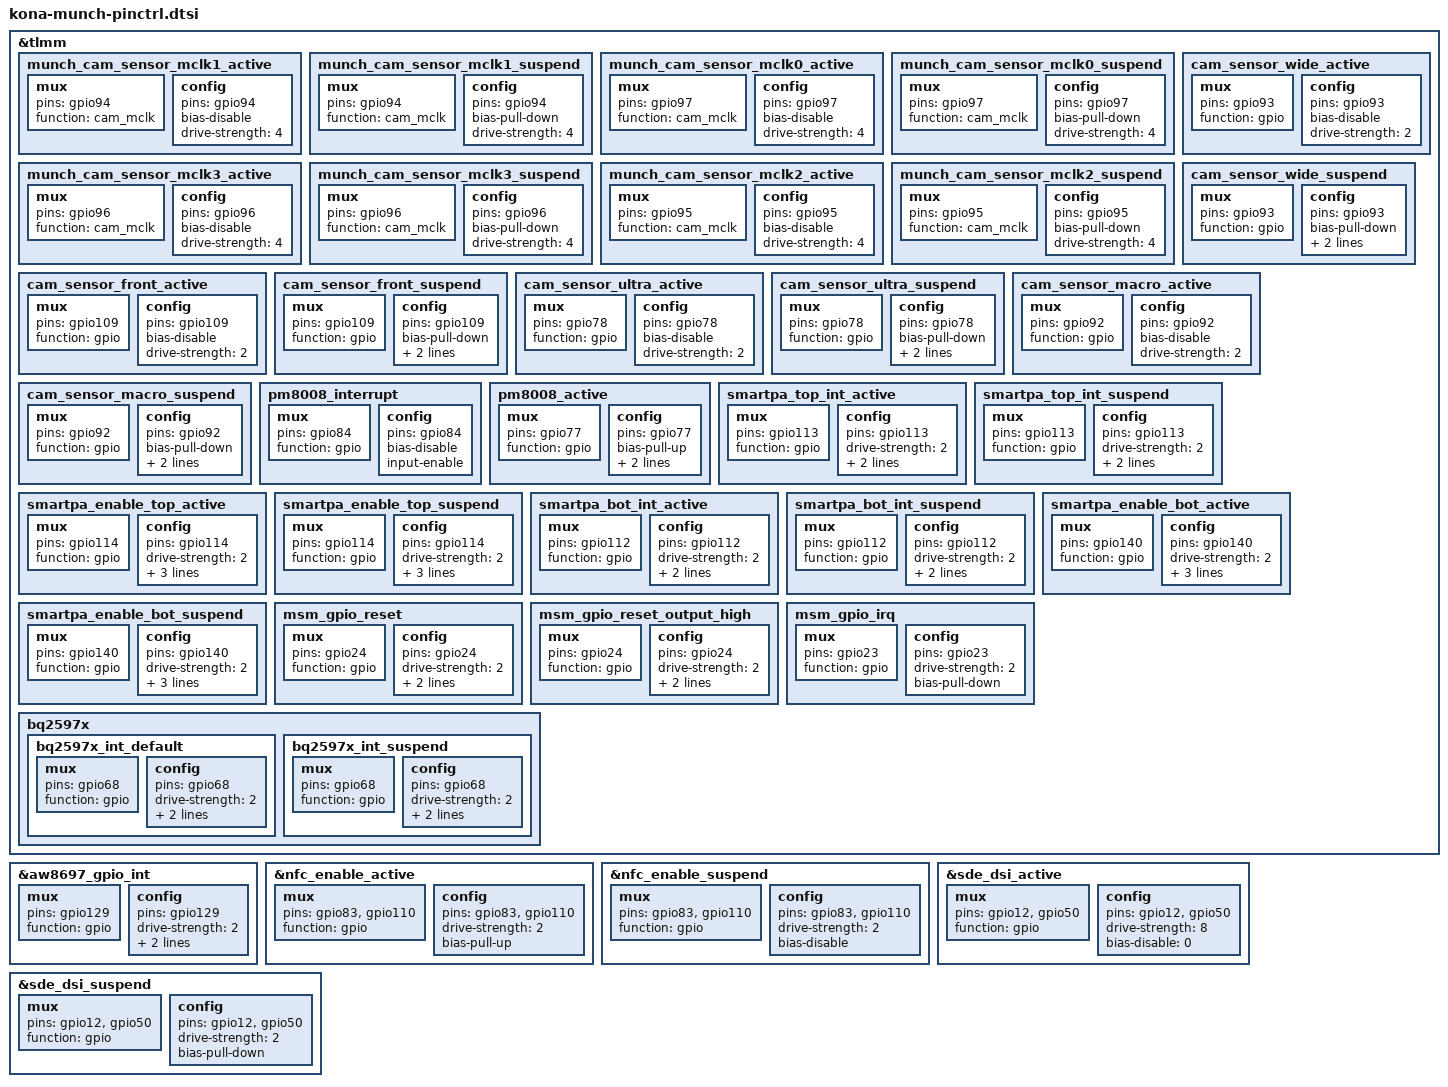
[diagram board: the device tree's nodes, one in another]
// SPDX-License-Identifier: GPL-2.0
/* Copyright (c) 2022, The Linux Foundation. All rights reserved.
 *
 * This program is free software; you can redistribute it and/or modify
 * it under the terms of the GNU General Public License version 2 and
 * only version 2 as published by the Free Software Foundation.
 *
 * This program is distributed in the hope that it will be useful,
 * but WITHOUT ANY WARRANTY; without even the implied warranty of
 * MERCHANTABILITY or FITNESS FOR A PARTICULAR PURPOSE.  See the
 * GNU General Public License for more details.
 */

&tlmm {
	munch_cam_sensor_mclk1_active: munch_cam_sensor_mclk1_active {
		mux {
			pins = "gpio94";
			function = "cam_mclk";
		};

		config {
			pins = "gpio94";
			bias-disable; /* No PULL */
			drive-strength = <4>; /* 4 MA */
		};
	};

	munch_cam_sensor_mclk1_suspend: munch_cam_sensor_mclk1_suspend {
		mux {
			pins = "gpio94";
			function = "cam_mclk";
		};

		config {
			pins = "gpio94";
			bias-pull-down; /* PULL DOWN */
			drive-strength = <4>; /* 4 MA */
		};
	};

	munch_cam_sensor_mclk0_active: munch_cam_sensor_mclk0_active {
		mux {
			pins = "gpio97";
			function = "cam_mclk";
		};

		config {
			pins = "gpio97";
			bias-disable; /* No PULL */
			drive-strength = <4>; /* 4 MA */
		};
	};

	munch_cam_sensor_mclk0_suspend: munch_cam_sensor_mclk0_suspend {
		mux {
			pins = "gpio97";
			function = "cam_mclk";
		};

		config {
			pins = "gpio97";
			bias-pull-down; /* PULL DOWN */
			drive-strength = <4>; /* 4 MA */
		};
	};

	munch_cam_sensor_mclk3_active: munch_cam_sensor_mclk3_active {
		mux {
			pins = "gpio96";
			function = "cam_mclk";
		};

		config {
			pins = "gpio96";
			bias-disable; /* No PULL */
			drive-strength = <4>; /* 4 MA */
		};
	};

	munch_cam_sensor_mclk3_suspend: munch_cam_sensor_mclk3_suspend {
		mux {
			pins = "gpio96";
			function = "cam_mclk";
		};

		config {
			pins = "gpio96";
			bias-pull-down; /* PULL DOWN */
			drive-strength = <4>; /* 4 MA */
		};
	};

	munch_cam_sensor_mclk2_active: munch_cam_sensor_mclk2_active {
		mux {
			pins = "gpio95";
			function = "cam_mclk";
		};

		config {
			pins = "gpio95";
			bias-disable; /* No PULL */
			drive-strength = <4>; /* 4 MA */
		};
	};

	munch_cam_sensor_mclk2_suspend: munch_cam_sensor_mclk2_suspend {
		mux {
			pins = "gpio95";
			function = "cam_mclk";
		};

		config {
			pins = "gpio95";
			bias-pull-down; /* PULL DOWN */
			drive-strength = <4>; /* 4 MA */
		};
	};

	cam_sensor_wide_active: cam_sensor_wide_active {
		mux {
			pins = "gpio93";
			function = "gpio";
		};

		config {
			pins = "gpio93";
			bias-disable; /* No PULL */
			drive-strength = <2>; /* 2 MA */
		};
	};

	cam_sensor_wide_suspend: cam_sensor_wide_suspend {
		mux {
			pins = "gpio93";
			function = "gpio";
		};

		config {
			pins = "gpio93";
			bias-pull-down; /* PULL DOWN */
			drive-strength = <2>; /* 2 MA */
			output-low;
		};
	};

	cam_sensor_front_active: cam_sensor_front_active {
		mux {
			pins = "gpio109";
			function = "gpio";
		};

		config {
			pins = "gpio109";
			bias-disable; /* No PULL */
			drive-strength = <2>; /* 2 MA */
		};
	};

	cam_sensor_front_suspend: cam_sensor_front_suspend {
		mux {
			pins = "gpio109";
			function = "gpio";
		};

		config {
			pins = "gpio109";
			bias-pull-down; /* PULL DOWN */
			drive-strength = <2>; /* 2 MA */
			output-low;
		};
	};

	cam_sensor_ultra_active: cam_sensor_ultra_active {
		mux {
			pins = "gpio78";
			function = "gpio";
		};

		config {
			pins = "gpio78";
			bias-disable; /* No PULL */
			drive-strength = <2>; /* 2 MA */
		};
	};

	cam_sensor_ultra_suspend: cam_sensor_ultra_suspend {
		mux {
			pins = "gpio78";
			function = "gpio";
		};

		config {
			pins = "gpio78";
			bias-pull-down; /* PULL DOWN */
			drive-strength = <2>; /* 2 MA */
			output-low;
		};
	};

	cam_sensor_macro_active: cam_sensor_macro_active {
		mux {
			pins = "gpio92";
			function = "gpio";
		};

		config {
			pins = "gpio92";
			bias-disable; /* No PULL */
			drive-strength = <2>; /* 2 MA */
		};
	};

	cam_sensor_macro_suspend: cam_sensor_macro_suspend {
		mux {
			pins = "gpio92";
			function = "gpio";
		};

		config {
			pins = "gpio92";
			bias-pull-down; /* PULL DOWN */
			drive-strength = <2>; /* 2 MA */
			output-low;
		};
	};

	pm8008_interrupt: pm8008_interrupt {
		mux {
			pins = "gpio84";
			function = "gpio";
		};

		config {
			pins = "gpio84";
			bias-disable;
			input-enable;
		};
	};

	pm8008_active: pm8008_active {
		mux {
			pins = "gpio77";
			function = "gpio";
		};

		config {
			pins = "gpio77";
			bias-pull-up;
			output-high;
			drive-strength = <2>;
		};
	};

	smartpa_top_int_active: smartpa_top_int_active {
		/* active state */
		mux {
		/* GPIO 113 Interrupt */
			pins = "gpio113";
			function = "gpio";
		};

		config {
			pins = "gpio113";
			drive-strength = <2>; /* 2 MA */
			bias-pull-up;
			input-enable;
		};
	};

	smartpa_top_int_suspend: smartpa_top_int_suspend {
		/* sleep state */
		mux {
		/* GPIO 113 Interrupt */
			pins = "gpio113";
			function = "gpio";
		};

		config {
			pins = "gpio113";
			drive-strength = <2>; /* 2 MA */
			bias-pull-up;
			input-enable;
		};
	};

	smartpa_enable_top_active: smartpa_enable_top_active {
		/* active state */
		mux {
		/* GPIO 114 rst pin */
			pins = "gpio114";
			function = "gpio";
		};

		config {
			pins = "gpio114";
			drive-strength = <2>;
			bias-disable;
			bias-pull-down;
			output-low;
		};
	};

	smartpa_enable_top_suspend: smartpa_enable_top_suspend {
		/* sleep state */
		mux {
			/* GPIO 114 rst pin */
			pins = "gpio114";
			function = "gpio";
		};

		config {
			pins = "gpio114";
			drive-strength = <2>;
			bias-disable;
			bias-pull-down;
			output-low;
		};
	};

	smartpa_bot_int_active: smartpa_bot_int_active {
		/* active state */
		mux {
		/* GPIO 112 Interrupt */
			pins = "gpio112";
			function = "gpio";
		};

		config {
			pins = "gpio112";
			drive-strength = <2>; /* 2 MA */
			bias-pull-up;
			input-enable;
		};
	};

	smartpa_bot_int_suspend: smartpa_bot_int_suspend {
		/* sleep state */
		mux {
		/* GPIO 112 Interrupt */
			pins = "gpio112";
			function = "gpio";
		};

		config {
			pins = "gpio112";
			drive-strength = <2>; /* 2 MA */
			bias-pull-up;
			input-enable;
		};
	};

	smartpa_enable_bot_active: smartpa_enable_bot_active {
		/* active state */
		mux {
		/* GPIO 140 rst pin */
			pins = "gpio140";
			function = "gpio";
		};

		config {
			pins = "gpio140";
			drive-strength = <2>;
			bias-disable;
			bias-pull-down;
			output-low;
		};
	};

	smartpa_enable_bot_suspend: smartpa_enable_bot_suspend {
		/* sleep state */
		mux {
			/* GPIO 140 rst pin */
			pins = "gpio140";
			function = "gpio";
		};

		config {
			pins = "gpio140";
			drive-strength = <2>;
			bias-disable;
			bias-pull-down;
			output-low;
		};
	};

	msm_gpio_reset: msm_gpio_reset {
		mux {
			pins = "gpio24";
			function = "gpio";
		};
		config {
			pins = "gpio24";
			drive-strength = <2>;
			bias-disable;
			output-low;
		};
	};

	msm_gpio_reset_output_high: msm_gpio_reset_output_high {
		mux {
			pins = "gpio24";
			function = "gpio";
		};
		config {
			pins = "gpio24";
			drive-strength = <2>;
			bias-disable;
			output-high;
		};
	};

	msm_gpio_irq: msm_gpio_irq {
		mux {
			pins = "gpio23";
			function = "gpio";
		};
		config {
			pins = "gpio23";
			drive-strength = <2>;
			bias-pull-down;
		};
	};

	bq2597x {
		bq2597x_int_default: bq2597x_int_default {
			mux {
				pins = "gpio68";
				function = "gpio";
			};

			config {
				pins = "gpio68";
				drive-strength = <2>; /* 2 MA */
				bias-pull-up;
				input-enable;
			};
		};

		bq2597x_int_suspend: bq2597x_int_suspend {
			mux {
				pins = "gpio68";
				function = "gpio";
			};

			config {
				pins = "gpio68";
				drive-strength = <2>; /* 2 MA */
				bias-pull-up;
				input-enable;
			};
		};
	};
};

&aw8697_gpio_int {
	mux {
		pins = "gpio129";
		function = "gpio";
	};

	config {
		pins = "gpio129";
		drive-strength = <2>;
		bias-disable;
		output-low;
	};
};

&nfc_enable_active {
	mux {
		pins = "gpio83", "gpio110";
		function = "gpio";
	};

	config {
		pins = "gpio83", "gpio110";
		drive-strength = <2>;
		bias-pull-up;
	};
};

&nfc_enable_suspend {
	mux {
		pins = "gpio83", "gpio110";
		function = "gpio";
	};

	config {
		pins = "gpio83", "gpio110";
		drive-strength = <2>;
		bias-disable;
	};
};

&sde_dsi_active {
	mux {
		pins = "gpio12", "gpio50";
		function = "gpio";
	};

	config {
		pins = "gpio12", "gpio50";
		drive-strength = <8>;	/* 8 mA */
		bias-disable = <0>;   /* no pull */
	};
};

&sde_dsi_suspend {
	mux {
		pins = "gpio12", "gpio50";
		function = "gpio";
	};

	config {
		pins = "gpio12", "gpio50";
		drive-strength = <2>;	/* 2 mA */
		bias-pull-down; 		/* PULL DOWN */
	};
};
